# MK20D5 register map
Vendor: Freescale Semiconductor, Inc.; Series: Kinetis_K; File version: 1.6
CPU: CM4 r0p1, little endian, no MPU, no FPU, VTOR, 4 interrupt priority bits
Registers are 32-bit, read-write, reset 0x0 unless marked. A register's access mark holds for its fields unless they carry their own. Offsets are from the block's base; [hi:lo] are bit positions; {n}, {i} and the like mark numbered series.

## SMC — System Mode Controller
Base 0x4007E000; register names take the prefix SMC_
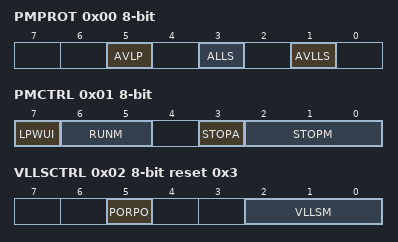
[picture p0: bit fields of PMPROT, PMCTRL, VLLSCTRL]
0x00 PMPROT 8-bit — Power Mode Protection Register
  [5] AVLP — Allow very low power modes
    0=VLPR, VLPW and VLPS are not allowed; 1=VLPR, VLPW and VLPS are allowed
  [3] ALLS — Allow low leakage stop mode
    0=LLS is not allowed; 1=LLS is allowed
  [1] AVLLS — Allow very low leakage stop mode
    0=Any VLLSx mode is not allowed; 1=Any VLLSx mode is allowed
0x01 PMCTRL 8-bit — Power Mode Control Register
  [7] LPWUI — Low Power Wake Up on Interrupt
    0=The system remains in a VLP mode on an interrupt; 1=The system exits to normal RUN mode on an interrupt
  [6:5] RUNM — Run Mode Control
    0=Normal run mode (RUN); 2=Very low power run mode (VLPR)
  [3] STOPA ro — Stop Aborted
    0=The previous stop mode entry was successsful; 1=The previous stop mode entry was aborted
  [2:0] STOPM — Stop Mode Control
    0=Normal stop (STOP); 2=Very low power stop (VLPS); 3=Low leakage stop (LLS); 4=Very low leakage stop (VLLSx); 6=Reseved
0x02 VLLSCTRL 8-bit reset 0x3 — VLLS Control Register
  [5] PORPO — POR Power Option
    0=POR detect circuit is enabled in VLLS0; 1=POR detect circuit is disabled in VLLS0
  [2:0] VLLSM — VLLS Mode Control.
    {v}=VLLS{v} (v=0..3)
0x03 PMSTAT 8-bit ro reset 0x1 — Power Mode Status Register
  [6:0] PMSTAT — When debug is enabled, the PMSTAT will not update to STOP or VLPS

## RCM — Reset Control Module
Base 0x4007F000; register names take the prefix RCM_
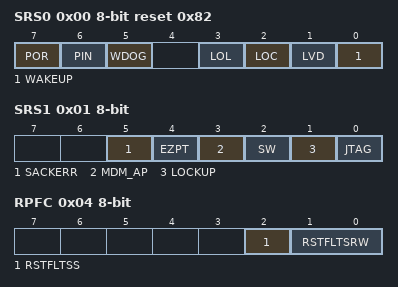
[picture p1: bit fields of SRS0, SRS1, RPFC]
0x00 SRS0 8-bit ro reset 0x82 — System Reset Status Register 0
  [7] POR — Power-on reset
    0=Reset not caused by POR; 1=Reset caused by POR
  [6] PIN — External reset pin
    0=Reset not caused by external reset pin; 1=Reset caused by external reset pin
  [5] WDOG — Watchdog
    0=Reset not caused by watchdog timeout; 1=Reset caused by watchdog timeout
  [3] LOL — Loss-of-lock reset
    0=Reset not caused by a loss of lock in the PLL; 1=Reset caused by a loss of lock in the PLL
  [2] LOC — Loss-of-clock reset
    0=Reset not caused by a loss of external clock; 1=Reset caused by a loss of external clock
  [1] LVD — Low-voltage detect reset
    0=Reset not caused by LVD trip or POR; 1=Reset caused by LVD trip or POR
  [0] WAKEUP — Low leakage wakeup reset
    0=Reset not caused by LLWU module wakeup source; 1=Reset caused by LLWU module wakeup source
0x01 SRS1 8-bit ro — System Reset Status Register 1
  [5] SACKERR — Stop Mode Acknowledge Error Reset
    0=Reset not caused by peripheral failure to acknowledge attempt to enter stop mode; 1=Reset caused by peripheral failure to acknowledge attempt to enter stop mode
  [4] EZPT — EzPort Reset
    0=Reset not caused by EzPort receiving the RESET command while the device is in EzPort mode; 1=Reset caused by EzPort receiving the RESET command while the device is in EzPort mode
  [3] MDM_AP — MDM-AP system reset request
    0=Reset not caused by host debugger system setting of the System Reset Request bit; 1=Reset caused by host debugger system setting of the System Reset Request bit
  [2] SW — Software
    0=Reset not caused by software setting of SYSRESETREQ bit; 1=Reset caused by software setting of SYSRESETREQ bit
  [1] LOCKUP — Core Lockup
    0=Reset not caused by core LOCKUP event; 1=Reset caused by core LOCKUP event
  [0] JTAG — JTAG generated reset
    0=Reset not caused by JTAG; 1=Reset caused by JTAG
0x04 RPFC 8-bit — Reset Pin Filter Control Register
  [2] RSTFLTSS — Reset pin filter select in stop mode
    0=All filtering disabled; 1=LPO clock filter enabled
  [1:0] RSTFLTSRW — Reset pin filter select in run and wait modes
    0=All filtering disabled; 1=Bus clock filter enabled for normal operation; 2=LPO clock filter enabled for normal operation
0x05 RPFW 8-bit — Reset Pin Filter Width Register
  [4:0] RSTFLTSEL — Reset pin filter bus clock select
    {v}=Bus clock filter count is {v+1} (v=0..31)
0x07 MR 8-bit ro — Mode Register
  [1] EZP_MS — EZP_MS_B pin state
    0=Pin negated (logic 1); 1=Pin asserted (logic 0)

## PTA — General Purpose Input/Output
Base 0x400FF000; register names take the prefix GPIOA_
0x00 PDOR — Port Data Output Register
  [31:0] PDO — Port Data Output
    0=Logic level 0 is driven on pin provided pin is configured for General Purpose Output; 1=Logic level 1 is driven on pin provided pin is configured for General Purpose Output
0x04 PSOR wo — Port Set Output Register
  [31:0] PTSO — Port Set Output
    0=Corresponding bit in PDORn does not change; 1=Corresponding bit in PDORn is set to logic one
0x08 PCOR wo — Port Clear Output Register
  [31:0] PTCO — Port Clear Output
    0=Corresponding bit in PDORn does not change; 1=Corresponding bit in PDORn is set to logic zero
0x0C PTOR wo — Port Toggle Output Register
  [31:0] PTTO — Port Toggle Output
    0=Corresponding bit in PDORn does not change; 1=Corresponding bit in PDORn is set to the inverse of its existing logic state
0x10 PDIR ro — Port Data Input Register
  [31:0] PDI — Port Data Input
    0=Pin logic level is logic zero or is configured for use by digital function; 1=Pin logic level is logic one
0x14 PDDR — Port Data Direction Register
  [31:0] PDD — Port data direction
    0=Pin is configured as general purpose input, if configured for the GPIO function; 1=Pin is configured for general purpose output, if configured for the GPIO function

## PTB — General Purpose Input/Output
Base 0x400FF040; register names take the prefix GPIOB_
Registers as PTA.

## PTC — General Purpose Input/Output
Base 0x400FF080; register names take the prefix GPIOC_
Registers as PTA; these are added or differ:
0x08 PCOR wo — Port Clear Output Register
  [31:0] PTCO — Port Clear Output
    0=Corresponding bit in PDORn does not change; 1=Corresponding bit in PDORn is set to logic zero

## PTD — General Purpose Input/Output
Base 0x400FF0C0; register names take the prefix GPIOD_
Registers as PTA.

## PTE — General Purpose Input/Output
Base 0x400FF100; register names take the prefix GPIOE_
Registers as PTA.
